# TLE985x register map
Vendor: Infineon Technologies AG; File version: 1.3
CPU: CM0 r0p0, little endian, no MPU, no FPU, 2 interrupt priority bits
Registers are 32-bit, read-write, no defined reset value unless marked. A register's access mark holds for its fields unless they carry their own. Offsets are from the block's base; [hi:lo] are bit positions; {n}, {i} and the like mark numbered series; 'fields as' and 'values as' point back to an identical list.

## BDRV
Base 0x40034000
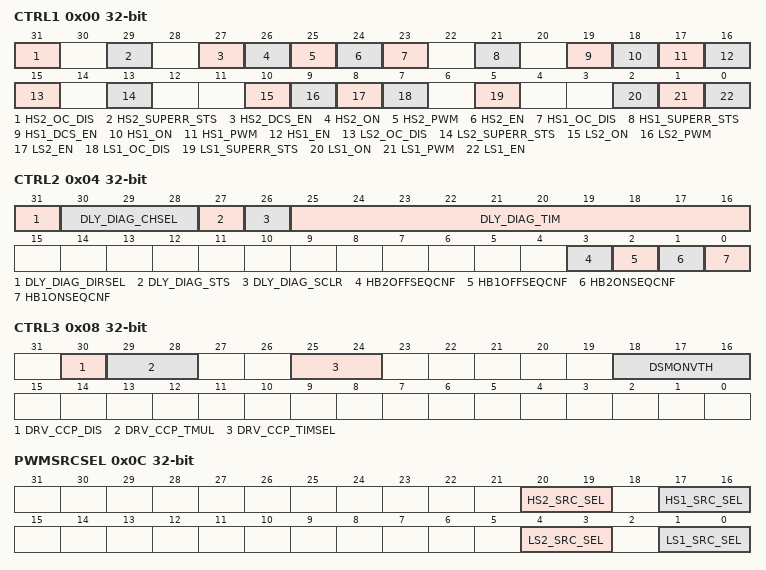
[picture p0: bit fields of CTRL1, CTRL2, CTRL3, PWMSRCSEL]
0x00 CTRL1 access per field — H-Bridge Driver Control 1
  [31] HS2_OC_DIS rw — High Side Driver Overcurrent Shutdown Select
    0=Global_Shutdown (all bridges will be shut down in case of overcurrent); 1=Local_Shutdown (only local driver will be shut down in case of overcurrent)
  [29] HS2_SUPERR_STS ro — High Side Driver 2 Supply Error Status
    0=NORMAL (supply is in required range.); 1=SUPPLY_ERROR (detected; this flag is an OR of the VSD_x_STS and VCP_x_STS flags.)
  [27] HS2_DCS_EN rw — High Side Driver 2 Diagnosis Current Source Enable
    0=DISABLE (disable current source); 1=ENABLE (enable current source; short diagnosis can be performed by evaluating the LSx/HSx_DS_STS Flag)
  [26] HS2_ON rw — High Side Driver 2 On
    0=OFF (Driver off); 1=ON (Driver on)
  [25] HS2_PWM rw — High Side Driver 2 PWM Enable
    0=DISABLE (disables control by PWM input); 1=ENABLE (enables control by PWM input)
  [24] HS2_EN rw — High Side Driver 2 Enable
    0=DISABLE (Driver circuit power off); 1=ENABLE (Driver circuit power on)
  [23] HS1_OC_DIS rw — High Side Driver Overcurrent Shutdown Select
    values as HS2_OC_DIS
  [21] HS1_SUPERR_STS ro — High Side Driver 1 Supply Error Status
    0=NORMAL (supply is in required range.); 1=SUPPLY_ERROR (detected; this flag is an OR of the VDS_x_STS and VCP_x_STS flags.)
  [19] HS1_DCS_EN rw — High Side Driver 1 Diagnosis Current Source Enable
    values as HS2_DCS_EN
  [18] HS1_ON rw — High Side Driver 1 On
    0=OFF (Driver off); 1=ON (Driver on)
  [17] HS1_PWM rw — High Side Driver 1 PWM Enable
    values as HS2_PWM
  [16] HS1_EN rw — High Side Driver 1 Enable
    values as HS2_EN
  [15] LS2_OC_DIS rw — Low Side Driver Overcurrent Shutdown Select
    values as HS2_OC_DIS
  [13] LS2_SUPERR_STS ro — Low Side Driver 2 Supply Error Status
    values as HS1_SUPERR_STS
  [10] LS2_ON rw — Low Side Driver 2 On
    0=OFF (Driver off); 1=ON (Driver on)
  [9] LS2_PWM rw — Low Side Driver 2 PWM Enable
    values as HS2_PWM
  [8] LS2_EN rw — Low Side Driver 2 Enable
    values as HS2_EN
  [7] LS1_OC_DIS rw — Low Side Driver 1 Overcurrent Shutdown Select
    values as HS2_OC_DIS
  [5] LS1_SUPERR_STS ro — Low Side Driver 1 Supply Error Status
    values as HS1_SUPERR_STS
  [2] LS1_ON rw — Low Side Driver 1 On
    0=OFF (Driver off); 1=ON (Driver on)
  [1] LS1_PWM rw — Low Side Driver 1 PWM Enable
    values as HS2_PWM
  [0] LS1_EN rw — Low Side Driver 1 Enable
    values as HS2_EN
0x04 CTRL2 access per field — H-Bridge Driver Control 2
  [31] DLY_DIAG_DIRSEL rw — Ext. power diag timer on / off select
    0=TURN OFF (measure turn off time); 1=TURN ON (measure turn on time)
  [30:28] DLY_DIAG_CHSEL rw — Ext. power diag timer channel select
    0=DISABLE (diag timer deactivated.); 1=HB1 LS select (measure LS1 on/off delay time.); 2=HB2 LS select (measure LS2 on/off delay time.); 5=HB1 HS select (measure HS1 on/off delay time.); 6=HB2 HS select (measure HS2 on/off delay time.)
  [27] DLY_DIAG_STS ro — Ext. power diag timer valid flag
    0=Diag_timer_invalid (diag timer measurement ongoing); 1=Diag_timer_valid (diag timer measurement finished)
  [26] DLY_DIAG_SCLR wo — Ext. power diag timer valid flag clear
    0=Diag timer valid not clear; 1=Diag timer valid clear
  [25:16] DLY_DIAG_TIM ro — Ext. power diag timer result register
  [3] HB2OFFSEQCNF rw — Half Bridge 2 Off Sequencer Configuration
    0=Normal Mode (OFF-Sequencer is disabled and driver operates with constant current.); 1=Sequencer Mode (OFF-Sequencer is enabled.)
  [2] HB1OFFSEQCNF rw — Half Bridge 1 Off Sequencer Configuration
    values as HB2OFFSEQCNF
  [1] HB2ONSEQCNF rw — Half Bridge 2 On Sequencer Configuration
    0=Normal Mode (ON-Sequencer is disabled and driver operates with constant current.); 1=Sequencer Mode (ON-Sequencer is enabled.)
  [0] HB1ONSEQCNF rw — Half Bridge 1 On Sequencer Configuration
    values as HB2ONSEQCNF
0x08 CTRL3 — H-Bridge Driver Control 3
  [30] DRV_CCP_DIS — Dynamic cross conduction protection Disable
    0=CCP Enable (dynamic ccp is active.); 1=CCP Disable (dynamic ccp is disabled, delayed gate clamp remains active.)
  [29:28] DRV_CCP_TMUL — Multiplier bits for cross conduction time settings in register DRV_CCP_TIMSEL
    0=MUL1 (DRV_CCP_TIMSEL value is multiplied by 1); 1=MUL2 (DRV_CCP_TIMSEL value is multiplied by 2); 2=MUL4 (DRV_CCP_TIMSEL value is multiplied by 4); 3=MUL8 (DRV_CCP_TIMSEL value is multiplied by 8)
  [25:24] DRV_CCP_TIMSEL — Minimum cross conduction protection time setting
    0=0.2us (200ns cross conduction protection time); 1=0.4us (400ns cross conduction protection time); 2=0.8us (800ns cross conduction protection time); 3=1.6us cross conduction protection time
  [18:16] DSMONVTH — Voltage Threshold for Drain-Source Monitoring of external FETs
    0=0.125_V (Threshold 0 for VDS at 0.125 V); 1=0.25_V (Threshold 1 for VDS at 0.25 V); 2=0.50_V (Threshold 2 for VDS at 0.50 V); 3=0.75_V (Threshold 3 for VDS at 0.75 V); 4=1.00_V (Threshold 4 for VDS at 1.00 V); 5=1.25_V (Threshold 5 for VDS at 1.25 V); 6=1.50_V (Threshold 6 for VDS at 1.50 V); 7=1.75_V (Threshold 7 for VDS at 1.75 V)
0x0C PWMSRCSEL — PWM Source Selection Register
  [all] fields
    0=CC60 (PWM output of CCU6); 1=CC61 (PWM output of CCU6); 2=COUT60 (PWM output of CCU6); 3=COUT61 (PWM output of CCU6)
  [20:19] HS2_SRC_SEL — HS2 PWM Source Selection
  [17:16] HS1_SRC_SEL — HS1 PWM Source Selection
  [4:3] LS2_SRC_SEL — LS2 PWM Source Selection
  [1:0] LS1_SRC_SEL — LS1 PWM Source Selection
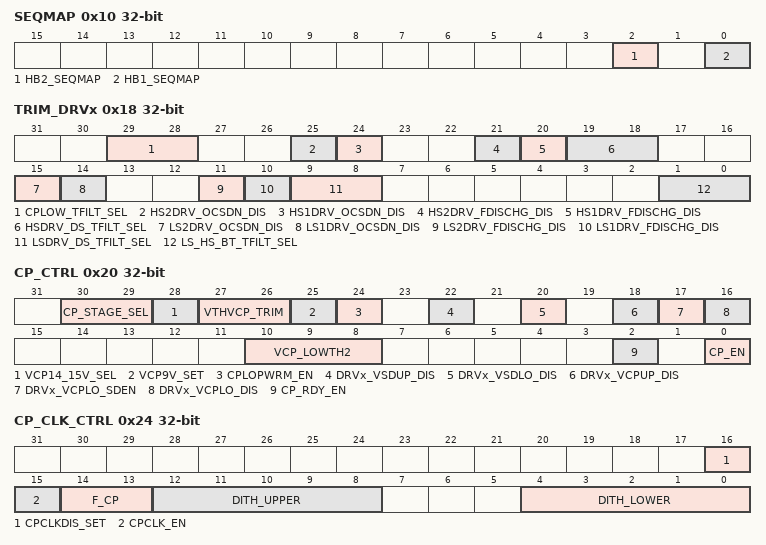
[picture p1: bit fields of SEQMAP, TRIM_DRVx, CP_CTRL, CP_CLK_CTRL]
0x10 SEQMAP — Slewrate Sequencer Mapping Register
  [2] HB2_SEQMAP — Half Bridge 2 Sequencer Mapping
    0=LS2 (slew rate sequencer is mapped to LS2); 1=HS2 (slew rate sequencer is mapped to HS2)
  [0] HB1_SEQMAP — Half Bridge 1 Sequencer Mapping
    0=LS1 (slew rate sequencer is mapped to LS1); 1=HS1 (slew rate sequencer is mapped to HS1)
0x18 TRIM_DRVx — Trimming of Driver
  [29:28] CPLOW_TFILT_SEL — Filter Time for Charge Pump Voltage Low Diagnosis
    0=4 us filter time; 1=8 us filter time; 2=16 us filter time; 3=32 us filter time
  [25] HS2DRV_OCSDN_DIS — High Side 2 Predriver in overcurrent situation disable
    0=Enable (Predriver shutdown in overcurrent situation enable); 1=Disable (Predriver shutdown in overcurrent situation disable)
  [24] HS1DRV_OCSDN_DIS — High Side 1 Predriver in overcurrent situation disable
    values as HS2DRV_OCSDN_DIS
  [21] HS2DRV_FDISCHG_DIS — High Side 2 Predriver fast discharge disable
    0=Enable (Predriver shutdown fast discharge enable); 1=Disable (Predriver shutdown fast discharge disable)
  [20] HS1DRV_FDISCHG_DIS — High Side 1 Predriver fast discharge disable
    values as HS2DRV_FDISCHG_DIS
  [19:18] HSDRV_DS_TFILT_SEL — Filter Time for Drain-Source Monitoring of High Side Drivers
    0=1 us filter time; 1=2 us filter time; 2=4 us filter time; 3=8 us filter time
  [15] LS2DRV_OCSDN_DIS — Low Side 2 Predriver in overcurrent situation disable
    values as HS2DRV_OCSDN_DIS
  [14] LS1DRV_OCSDN_DIS — Low Side 1 Predriver in overcurrent situation disable
    values as HS2DRV_OCSDN_DIS
  [11] LS2DRV_FDISCHG_DIS — Low Side 2 Predriver fast discharge disable
    values as HS2DRV_FDISCHG_DIS
  [10] LS1DRV_FDISCHG_DIS — Low Side 1 Predriver fast discharge disable
    values as HS2DRV_FDISCHG_DIS
  [9:8] LSDRV_DS_TFILT_SEL — Filter Time for Drain-Source Monitoring of Low Side Drivers
    values as HSDRV_DS_TFILT_SEL
  [1:0] LS_HS_BT_TFILT_SEL — Blanking Time for Drain-Source Monitoring of Low / High Side Drivers
    values as HSDRV_DS_TFILT_SEL
0x20 CP_CTRL — Charge Pump Control and Status Register
  [30:29] CP_STAGE_SEL — Charge Pump Output Voltage Trimming
    0=2-stage mode enabled; 1=1-stage1 (single stage mode enable (1st stage)); 2=1-stage2 (single stage mode enable (2nd stage)); 3=automatic switch to single stage mode above 18V VSD (2nd stage) and switching back to 2-stage mode below 17V VSD
  [28] VCP14_15V_SEL — Charge Pump 15V/14V Output Voltage Sel
    0=14V (output voltage set to 14V); 1=15V (output voltage set to 15V)
  [27:26] VTHVCP_TRIM — Charge Pump Output Voltage Trimming
    0=0.0_V (default); 1=0.5_V (plus 0.5V nom at 15V); 2=1.0_V (plus 1.0V nom at 15V); 3=1.5_V (plus 1.5V nom at 15V)
  [25] VCP9V_SET — Charge Pump 9 V Output Voltage Set
    0=15_14V Set (output voltage set according to VCP14_15V_SEL); 1=9V Set (output voltage set to 9V)
  [24] CPLOPWRM_EN — Charge Pump Low Power Mode Enable
    0=Low Power Mode Disable (low power mode inactive); 1=Low Power Mode Enable (low power mode active)
  [22] DRVx_VSDUP_DIS — Driver On VSD Upper Voltage Disable
    0=Driver Enable (DRVx on VSD overvoltage enable.); 1=Driver Disable (DRVx on VSD overvoltage disable.)
  [20] DRVx_VSDLO_DIS — Driver On VSD Lower Voltage Disable
    0=Driver Enable (DRVx on VSD undervoltage enable.); 1=Driver Disable (DRVx on VSD undervoltage disable.)
  [18] DRVx_VCPUP_DIS — Driver On Charge Pump Upper Voltage Disable
    0=Driver Enable (DRVx on Charge Pumpe overvoltage enable.); 1=Driver Disable (DRVx on Charge Pump overvoltage disable.)
  [17] DRVx_VCPLO_SDEN — Driver Charge Pump Low Voltage Shut-Down
    0=Shut-Down Disable (DRVx Shut-Down for Charge Pump undervoltage disable.); 1=Shut-Down Enable (DRVx Shut-Down for Charge Pump undervoltage enable.)
  [16] DRVx_VCPLO_DIS — Driver On Charge Pump Low Voltage Disable
    0=Driver Enable (DRVx on Charge Pump undervoltage enable.); 1=Driver Disable (DRVx on Charge Pump undervoltage disable.)
  [10:8] VCP_LOWTH2 — Charge Pump Output Voltage Lower Threshold Detection Level
    0=7.325_V (Threshold 0); 1=7.654_V (Threshold 1); 2=7.982_V (Threshold 2); 3=8.309_V (Threshold 3); 4=8.638_V (Threshold 4); 5=8.966_V (Threshold 5); 6=9.293_V (Threshold 6); 7=9.620_V (Threshold 7)
  [2] CP_RDY_EN — Bridge Driver on Charge Pump Ready Enable
    0=OFF (Bridge Driver can be immediately enabled); 1=ON (Bridge Driver can only be enabled when Charge Pump is ready)
  [0] CP_EN — Charge Pump Enable
    0=DISABLE (Charge Pump, circuit power off); 1=ENABLE (Charge Pump, circuit power on)
0x24 CP_CLK_CTRL — Charge Pump Clock Control Register
  [16] CPCLKDIS_SET — Charge Pump Clock Set If Disabled
    0=LOW (Charge Pump Clock is 0 if disabled); 1=HIGH (Charge Pump Clock is 1 if disabled)
  [15] CPCLK_EN — Charge Pump Clock Enable
    0=DISABLE (Charge Pump Clock is switched off and has value of according to CPCLKDIS_SET); 1=ENABLE (Charge Pump Clock is running)
  [14:13] F_CP — MSB of CP_CLK divider
  [12:8] DITH_UPPER — CP_CLK upper frequency boundary during dithering
  [4:0] DITH_LOWER — CP_CLK lower frequency boundary during dithering
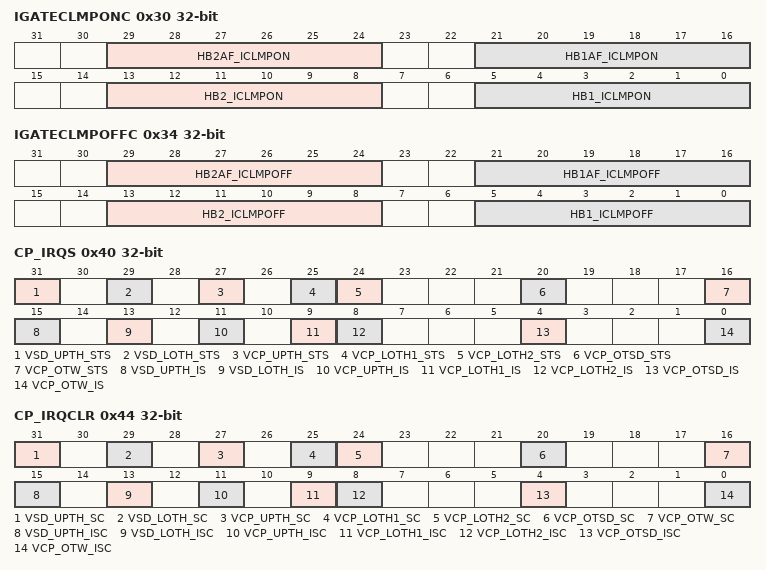
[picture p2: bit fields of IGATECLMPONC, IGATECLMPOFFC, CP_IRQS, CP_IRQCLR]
0x30 IGATECLMPONC — Gate Current Clamping Value in ON State
  [all] fields
    0=min. current (ICHGmin); 63=max. current (ICHGmax)
  [29:24] HB2AF_ICLMPON — Half Bridge 2-active freewheeling-current clamping value for ON state
  [21:16] HB1AF_ICLMPON — Half Bridge 1-active freewheeling-current clamping value for ON state
  [13:8] HB2_ICLMPON — Half Bridge 2-current clamping value for ON state
  [5:0] HB1_ICLMPON — Half Bridge 1-current clamping value for ON state
0x34 IGATECLMPOFFC — Gate Current Clamping Value in OFF State
  [all] fields
    0=min. current (IDISCHGmin); 63=max. current (IDISCHGmax)
  [29:24] HB2AF_ICLMPOFF — Half Bridge 2-active freewheeling-current clamping value for OFF state
  [21:16] HB1AF_ICLMPOFF — Half Bridge 1-active freewheeling-current clamping value for OFF state
  [13:8] HB2_ICLMPOFF — Half Bridge 2-current clamping value for OFF state
  [5:0] HB1_ICLMPOFF — Half Bridge 1-current clamping value for OFF state
0x40 CP_IRQS — Charge Pump Status Register
  [31] VSD_UPTH_STS — Driver Supply MU High Status
    0=ok (Driver Supply Voltage ok, no overvoltage detected); 1=too_high (Driver Supply Voltage too high, overvoltage on VSD Pin detected)
  [29] VSD_LOTH_STS — Driver Supply MU Low Status
    0=ok (Driver Supply Voltage ok, no undervoltage detected.); 1=too_low (Driver Supply Voltage too low, undervoltage on VSD Pin detected.)
  [27] VCP_UPTH_STS — Charge Pump MU High Status
    0=ok (Charge Pump Output Voltage ok, no overvoltage detected); 1=too_high (Charge Pump Output Voltage too high, overvoltage on charge pump output detected)
  [25] VCP_LOTH1_STS — Charge Pump MU Low Status
    0=ok (Charge Pump Output Voltage ok, no undervoltage detected.); 1=too_low (Charge Pump Output Voltage too low, undervoltage on chargepump output detected.)
  [24] VCP_LOTH2_STS — Charge Pump Low Status
    values as VCP_LOTH1_STS
  [20] VCP_OTSD_STS — Charge Pump Overtemperature Shutdown Status
    0=ok (Charge Pump Overtemperature Shutdown Threshold not reached, no charge pump overtemperature shutdown detected.); 1=shutdown (Charge Pump Overtemperature Shutdown, overtemperature shutdown on charge pump occured.)
  [16] VCP_OTW_STS — Charge Pump Overtemperature Warning Status
    0=ok (Charge Pump Temperature ok, no charge pump overtemperature warning detected.); 1=warning (harge Pump Overtemperature Warning, overtemperature threshold on charge pump reached.)
  [15] VSD_UPTH_IS — Driver Supply MU High Interrupt Status
    values as VSD_UPTH_STS
  [13] VSD_LOTH_IS — Driver Supply MU Low Interrupt Status
    values as VSD_LOTH_STS
  [11] VCP_UPTH_IS — Charge Pump MU High Interrupt Status
    values as VCP_UPTH_STS
  [9] VCP_LOTH1_IS — Charge Pump MU Low Interrupt Status
    0=ok (Charge Pump Output Voltage ok, no undervoltage detected.); 1=too_low (Charge Pump Output Voltage too low, undervoltage on charge pump output detected.)
  [8] VCP_LOTH2_IS — Charge Pump Low Interrupt Status
    values as VCP_LOTH1_STS
  [4] VCP_OTSD_IS — Charge Pump Overtemperature Shutdown Interrupt Status
    values as VCP_OTSD_STS
  [0] VCP_OTW_IS — Charge Pump Overtemperature Warning Interrupt Status
    0=ok (Charge Pump Temperature ok, no charge pump overtemperature warning detected.); 1=warning (Charge Pump Overtemperature Warning, overtemperature threshold on charge pump reached.)
0x44 CP_IRQCLR wo — Charge Pump Interrupt Status Clear Register
  [all] fields
    0=no Clear; 1=Clear
  [31] VSD_UPTH_SC — Driver Supply MU High Status Clear
  [29] VSD_LOTH_SC — Driver Supply MU Low Status Clear
  [27] VCP_UPTH_SC — Charge Pump MU High Status Clear
  [25] VCP_LOTH1_SC — Charge Pump MU Low Status Clear
  [24] VCP_LOTH2_SC — Charge Pump Low Status Clear
  [20] VCP_OTSD_SC — Charge Pump Over-temperature Shutdown Status Clear
  [16] VCP_OTW_SC — Charge Pump Over-temperature Warning Status Clear
  [15] VSD_UPTH_ISC — Driver Supply MU High Interrupt Status Clear
  [13] VSD_LOTH_ISC — Driver Supply MU Low Interrupt Status Clear
  [11] VCP_UPTH_ISC — Charge Pump MU High Interrupt Status Clear
  [9] VCP_LOTH1_ISC — Charge Pump MU Low Interrupt Status Clear
  [8] VCP_LOTH2_ISC — Charge Pump Low Interrupt Status Clear
  [4] VCP_OTSD_ISC — Charge Pump Over-temperature Shutdown Interrupt Status Clear
  [0] VCP_OTW_ISC — Charge Pump Over-temperature Warning Interrupt Status Clear
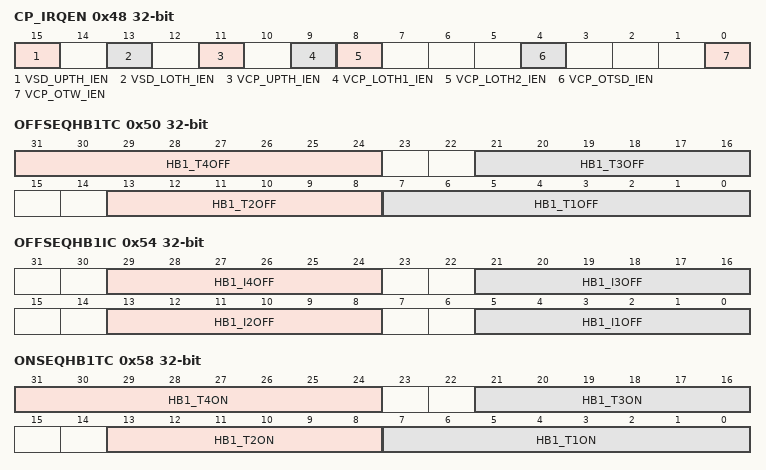
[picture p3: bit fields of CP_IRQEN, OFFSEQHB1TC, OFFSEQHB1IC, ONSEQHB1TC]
0x48 CP_IRQEN — Charge Pump Interrupt Enable Register
  [all] fields
    0=disable; 1=enable
  [15] VSD_UPTH_IEN — Driver Supply MU High Interrupt Enable
  [13] VSD_LOTH_IEN — Driver Supply MU Low Interrupt Enable
  [11] VCP_UPTH_IEN — Charge Pump MU High Interrupt Enable
  [9] VCP_LOTH1_IEN — Charge Pump MU Low Interrupt Enable
  [8] VCP_LOTH2_IEN — Charge Pump Low Interrupt Enable
  [4] VCP_OTSD_IEN — Charge Pump Over-temperature Shutdown Interrupt Enable
  [0] VCP_OTW_IEN — Charge Pump Over-temperature Warning Interrupt Enable
0x50 OFFSEQHB1TC — Turn-off Slewrate Sequencer Half Bridge 1 Time Control
  [31:24] HB1_T4OFF — Half Bridge 1-slew rate sequencer off-phase 4 time setting
    0=50ns phase duration; 255=12.8us phase duration
  [21:16] HB1_T3OFF — Half Bridge 1-slew rate sequencer off-phase 3 time setting
    0=50ns phase duration; 63=3.2us phase duration
  [13:8] HB1_T2OFF — Half Bridge 1-slew rate sequencer off-phase 2 time setting
    0=50ns phase duration; 63=3.2us phase duration
  [7:0] HB1_T1OFF — Half Bridge 1-slew rate sequencer off-phase 1 time setting
    0=50ns phase duration; 255=12.8us phase duration
0x54 OFFSEQHB1IC — Turn-off Slewrate Sequencer Half Bridge 1 Current Control
  [all] fields
    0=min. current (IDISCHGmin); 63=max. current (IDISCHGmax)
  [29:24] HB1_I4OFF — Half Bridge 1-slew rate sequencer off-phase 4 current setting
  [21:16] HB1_I3OFF — Half Bridge 1-slew rate sequencer off-phase 3 current setting
  [13:8] HB1_I2OFF — Half Bridge 1-slew rate sequencer-off phase 2 current setting
  [5:0] HB1_I1OFF — Half Bridge 1-slew rate sequencer off-phase 1 current setting
0x58 ONSEQHB1TC — Turn-on Slewrate Sequencer Half Bridge 1 Time Control
  [31:24] HB1_T4ON — Half Bridge 1-slew rate sequencer on-phase 4 time setting
    0=50ns phase duration; 255=12.8us phase duration
  [21:16] HB1_T3ON — Half Bridge 1-slew rate sequencer on-phase 3 time setting
    0=50ns phase duration; 63=3.2us phase duration
  [13:8] HB1_T2ON — Half Bridge 1-slew rate sequencer on-phase 2 time setting
    0=50ns phase duration; 63=3.2us phase duration
  [7:0] HB1_T1ON — Half Bridge 1-slew rate sequencer on-phase 1 time setting
    0=50ns phase duration; 255=12.8us phase duration
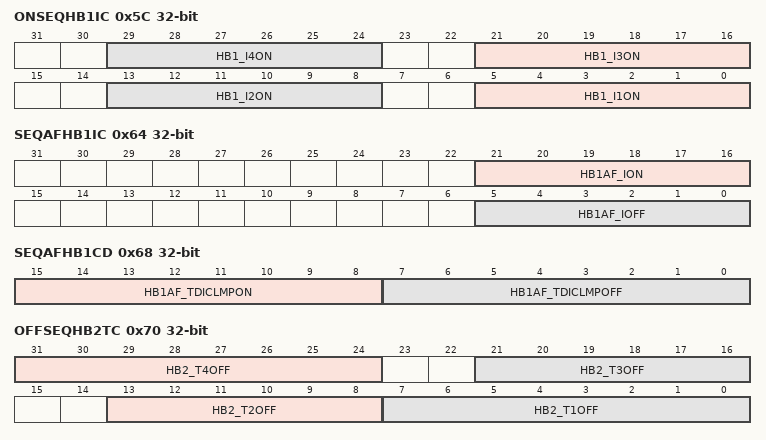
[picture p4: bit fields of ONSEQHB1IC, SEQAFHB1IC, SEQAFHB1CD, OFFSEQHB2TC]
0x5C ONSEQHB1IC — Turn-on Slewrate Sequencer Half Bridge 1 Current Control
  [all] fields
    0=min. current (ICHGmin); 63=max. current (ICHGmax)
  [8n-3:8n-8] HB1_I{n}ON (n=1..4) — Half Bridge 1-slew rate sequencer on-phase {n} current setting
0x64 SEQAFHB1IC — Slewrate Sequencer-Active Freewheeling-Half Bridge 1 Current Control
  [21:16] HB1AF_ION — Half Bridge 1-active freewheeling-slew rate sequencer on-phase current setting
    0=min. current (IDISCHGmin); 63=max. current (IDISCHGmax)
  [5:0] HB1AF_IOFF — Half Bridge 1-active freewheeling-slew rate sequencer off-phase current setting
    0=min. current (IDISCHGmin); 63=max. current (IDISCHGmax)
0x68 SEQAFHB1CD — Slewrate Sequencer-Active Freewheeling- Half Bridge 1 Clamping Current Delay
  [15:8] HB1AF_TDICLMPON — Clamping current delay during active freewheeling for switch on
    0=50ns phase duration; 255=12.8us phase duration
  [7:0] HB1AF_TDICLMPOFF — Clamping current delay during active freewheeling for switch off
    0=50ns phase duration; 255=12.8us phase duration
0x70 OFFSEQHB2TC — Turn-off Slewrate Sequencer Half Bridge 2 Time Control
  [31:24] HB2_T4OFF — Half Bridge 2-slew rate sequencer off-phase 4 time setting
    0=50ns phase duration; 255=12.8us phase duration
  [21:16] HB2_T3OFF — Half Bridge 2-slew rate sequencer off-phase 3 time setting
    0=50ns phase duration; 63=3.2us phase duration
  [13:8] HB2_T2OFF — Half Bridge 2-slew rate sequencer off-phase 2 time setting
    0=50ns phase duration; 63=3.2us phase duration
  [7:0] HB2_T1OFF — Half Bridge 2-slew rate sequencer off-phase 1 time setting
    0=50ns phase duration; 255=12.8us phase duration
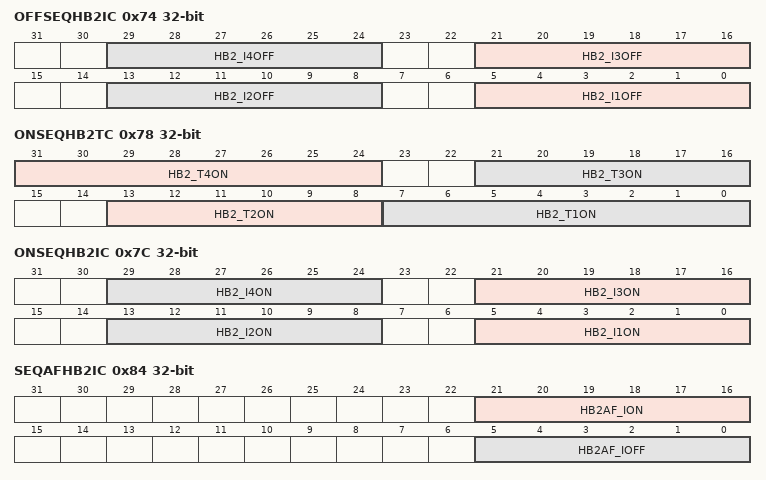
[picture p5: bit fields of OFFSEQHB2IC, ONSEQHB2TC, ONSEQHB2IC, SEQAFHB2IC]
0x74 OFFSEQHB2IC — Turn-off Slewrate Sequencer Half Bridge 2 Current Control
  [all] fields
    0=min. current (IDISCHGmin); 63=max. current (IDISCHGmax)
  [8n-3:8n-8] HB2_I{n}OFF (n=1..4) — Half Bridge 2-slew rate sequencer off-phase {n} current setting
0x78 ONSEQHB2TC — Turn-on Slewrate Sequencer Half Bridge 2 Time Control
  [31:24] HB2_T4ON — Half Bridge 2-slew rate sequencer on-phase 4 time setting
    0=50ns phase duration; 255=12.8us phase duration
  [21:16] HB2_T3ON — Half Bridge 2-slew rate sequencer on-phase 3 time setting
    0=50ns phase duration; 63=3.2us phase duration
  [13:8] HB2_T2ON — Half Bridge 2-slew rate sequencer on-phase 2 time setting
    0=50ns phase duration; 63=3.2us phase duration
  [7:0] HB2_T1ON — Half Bridge 2-slew rate sequencer on-phase 1 time setting
    0=50ns phase duration; 255=12.8us phase duration
0x7C ONSEQHB2IC — Turn-on Slewrate Sequencer Half Bridge 2 Current Control
  [all] fields
    0=min. current (ICHGmin); 63=max. current (ICHGmax)
  [8n-3:8n-8] HB2_I{n}ON (n=1..4) — Half Bridge 2-slew rate sequencer on-phase {n} current setting
0x84 SEQAFHB2IC — Slewrate Sequencer-Active Freewheeling- Half Bridge 2 Current Control
  [21:16] HB2AF_ION — Half Bridge 2-active freewheeling-slew rate sequencer on-phase current setting
    0=min. current (IDISCHGmin); 63=max. current (IDISCHGmax)
  [5:0] HB2AF_IOFF — Half Bridge 2-active freewheeling-slew rate sequencer off-phase current setting
    0=min. current (IDISCHGmin); 63=max. current (IDISCHGmax)
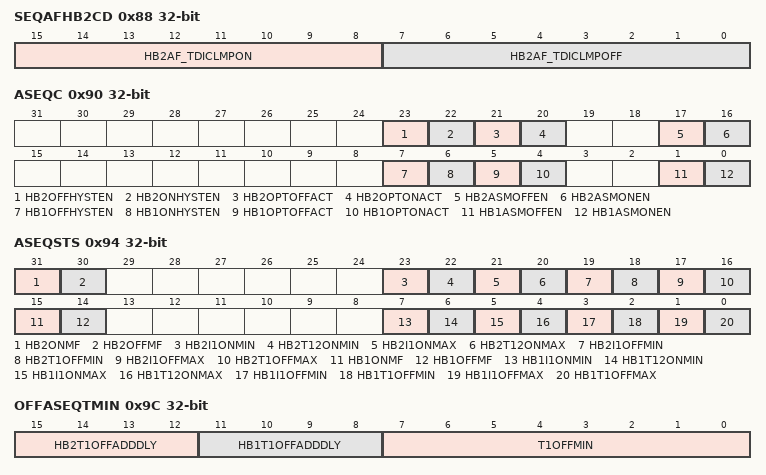
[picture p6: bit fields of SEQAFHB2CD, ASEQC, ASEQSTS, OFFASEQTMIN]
0x88 SEQAFHB2CD — Slewrate Sequencer-Active Freewheeling- Half Bridge 2 Clamping Current Delay
  [15:8] HB2AF_TDICLMPON — Clamping current delay during active freewheeling for switch on
    0=50ns phase duration; 255=12.8us phase duration
  [7:0] HB2AF_TDICLMPOFF — Clamping current delay during active freewheeling for switch off
    0=50ns phase duration; 255=12.8us phase duration
0x90 ASEQC — Adaptive Slewrate Sequencer Control Register
  [23] HB2OFFHYSTEN — Half Bridge 2 Optimizer Hysteresis for Switch Off Enable Bit
    0=OFF (current optimizer hysteresis is not enabled); 1=ON (current optimizer hysteresis is enabled)
  [22] HB2ONHYSTEN — Half Bridge 2 Optimizer Hysteresis for Switch On Enable Bit
    values as HB2OFFHYSTEN
  [21] HB2OPTOFFACT — Half Bridge 2 Optimizer for Switch Off Active Bit
    0=OFF (current optimizer is not active); 1=ON (current optimizer is active)
  [20] HB2OPTONACT — Half Bridge 2 Optimizer for Switch On Active Bit
    values as HB2OPTOFFACT
  [17] HB2ASMOFFEN — Half Bridge 2 Adaptive Sequencer Mode for Switch Off Enable
    0=Disable (adaptive slew rate sequencer is disabled); 1=Enable (adaptive slew rate sequencer is enabled)
  [16] HB2ASMONEN — Half Bridge 2 Adaptive Sequencer Mode for Switch On Enable
    values as HB2ASMOFFEN
  [7] HB1OFFHYSTEN — Half Bridge 1 Optimizer Hysteresis for Switch Off Enable Bit
    values as HB2OFFHYSTEN
  [6] HB1ONHYSTEN — Half Bridge 1 Optimizer Hysteresis for Switch On Enable Bit
    values as HB2OFFHYSTEN
  [5] HB1OPTOFFACT — Half Bridge 1 Optimizer for Switch Off Active Bit
    values as HB2OPTOFFACT
  [4] HB1OPTONACT — Half Bridge 1 Optimizer for Switch On Active Bit
    values as HB2OPTOFFACT
  [1] HB1ASMOFFEN — Half Bridge 1 Adaptive Sequencer Mode for Switch Off Enable
    values as HB2ASMOFFEN
  [0] HB1ASMONEN — Half Bridge 1 Adaptive Sequencer Mode for Switch On Enable
    values as HB2ASMOFFEN
0x94 ASEQSTS ro — Adaptive Slewrate Sequencer Status Register
  [31] HB2ONMF — Half Bridge 2- On Adaptive Mode Measurement Failure
    0=no Error (No Measurement Failure); 1=Error (Measurement Failure)
  [30] HB2OFFMF — Half Bridge 2- Off Adaptive Mode Measurement Failure
    values as HB2ONMF
  [23] HB2I1ONMIN — Half Bridge 2-I1 On Min Value reached
    0=no Error (Min Value not reached); 1=Error (Min Value reached)
  [22] HB2T12ONMIN — Half Bridge 2-T12 On Min Value reached
    values as HB2I1ONMIN
  [21] HB2I1ONMAX — Half Bridge 2-I1 On Max Value reached
    0=no Error (Max Value not reached); 1=Error (Max Value reached)
  [20] HB2T12ONMAX — Half Bridge 2-T12 On Max Value reached
    values as HB2I1ONMAX
  [19] HB2I1OFFMIN — Half Bridge 2-I1 Off Min Value reached
    values as HB2I1ONMIN
  [18] HB2T1OFFMIN — Half Bridge 2-T1 Off Min Value reached
    values as HB2I1ONMIN
  [17] HB2I1OFFMAX — Half Bridge 2-I1 Off Max Value reached
    values as HB2I1ONMAX
  [16] HB2T1OFFMAX — Half Bridge 2-T1 Off Max Value reached
    values as HB2I1ONMAX
  [15] HB1ONMF — Half Bridge 1-On Adaptive Mode Measurement Failure
    values as HB2ONMF
  [14] HB1OFFMF — Half Bridge 1-Off Adaptive Mode Measurement Failure
    values as HB2ONMF
  [7] HB1I1ONMIN — Half Bridge 1-I1 On Min Value reached
    values as HB2I1ONMIN
  [6] HB1T12ONMIN — Half Bridge 1-T12 On Min Value reached
    values as HB2I1ONMIN
  [5] HB1I1ONMAX — Half Bridge 1-I1 On Max Value reached
    values as HB2I1ONMAX
  [4] HB1T12ONMAX — Half Bridge 1-T12 On Max Value reached
    values as HB2I1ONMAX
  [3] HB1I1OFFMIN — Half Bridge 1-I1 Off Min Value reached
    values as HB2I1ONMIN
  [2] HB1T1OFFMIN — Half Bridge 1-T1 Off Min Value reached
    values as HB2I1ONMIN
  [1] HB1I1OFFMAX — Half Bridge 1-I1 Off Max Value reached
    values as HB2I1ONMAX
  [0] HB1T1OFFMAX — Half Bridge 1-T1 Off Max Value reached
    values as HB2I1ONMAX
0x98 ONASEQTMIN — Turn ON Adaptive Slewrate Sequencer Minimum Time Setting
  [7:0] T12ONMIN — Slew rate sequencer on-phase 12 min. time setting
    0=50ns phase duration; 255=12.8us phase duration
0x9C OFFASEQTMIN — Turn OFF Adaptive Slewrate Sequencer Minimum Time Setting
  [15:12] HB2T1OFFADDDLY — HB2 adaptive sequencer T1OFF additional delay setting.
    0=0ns (0ns added to HB2T1OFF); 15=750ns added to HB2T1OFF
  [11:8] HB1T1OFFADDDLY — HB1 adaptive sequencer T1OFF additional delay setting.
    0=0ns (0ns added to HB1T1OFF); 15=750ns added to HB1T1OFF
  [7:0] T1OFFMIN — Slew rate sequencer off-phase 1 min. time setting
    0=50ns phase duration; 255=12.8us phase duration
0xA0 ASEQIONMIN — Adaptive Slewrate Sequencer On Phase Minimum Current Setting
  [5:0] I1ONMIN — Slew rate sequencer on-phase 1 min. current setting
    0=min. current (ICHGmin); 63=max. current (ICHGmax)
0xA4 ASEQIOFFMIN — Adaptive Slewrate Sequencer Off Phase Minimum Current Setting
  [5:0] I1OFFMIN — Slew rate sequencer off-phase 1 min. current setting
    0=min. current (IDISCHGmin); 63=max. current (IDISCHGmax)
0xA8 ONASEQTMAX — Adaptive Slewrate On Sequencer Maximum Time Setting
  [7:0] T12ONMAX — Slew rate sequencer on-phase 12 max. time setting
    0=50ns phase duration; 255=12.8us phase duration
0xAC OFFASEQTMAX — Adaptive Slewrate Off Sequencer Maximum Time Setting
  [7:0] T1OFFMAX — Slew rate sequencer off-phase 1 max. time setting
    0=50ns phase duration; 255=12.8us phase duration
0xB0 ASEQIONMAX — Adaptive Slewrate Sequencer On Phase Maximum Current Setting
  [5:0] I1ONMAX — Slew rate sequencer on-phase 1 max. current setting
    0=min. current (ICHGmin); 63=max. current (ICHGmax)
0xB4 ASEQIOFFMAX — Adaptive Slewrate Sequencer Off Phase Maximum Current Setting
  [5:0] I1OFFMAX — Slew rate sequencer off-phase 1 max. current setting
    0=min. current (IDISCHGmin); 63=max. current (IDISCHGmax)
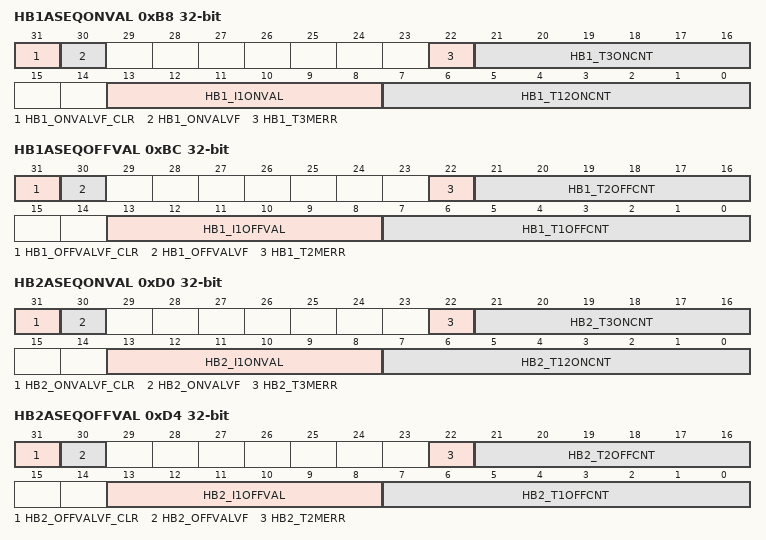
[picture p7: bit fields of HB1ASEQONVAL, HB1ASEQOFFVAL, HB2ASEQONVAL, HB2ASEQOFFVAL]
0xB8 HB1ASEQONVAL access per field — Half Bridge 1 Adaptive Sequencer On Values
  [31] HB1_ONVALVF_CLR wo — Half Bridge 1-Turn on slew rate values Valid Flag - Clear.
    0=NOT CLEAR (no clear of HB1_ONVALVF flag); 1=CLEAR (clear of HB1_ONVALVF flag)
  [30] HB1_ONVALVF rw — Half Bridge 1-Turn on slew rate values - Valid Flag.
    0=NOT VALID (no new valid LS1/HS1_ON values available); 1=VALID (LS1/HS1_ON fields contain valid data and have not been read)
  [22] HB1_T3MERR ro — Half Bridge 1-T3 Measurement Error.
    0=VALID (T3 value valid); 1=ERROR (T3 value not valid - Measurement Error)
  [21:16] HB1_T3ONCNT ro — Half Bridge 1-Turn on slew rate-time value measured from beginning of phase 3 to end of phase 3.
    0=50ns phase duration; 63=3.2us phase duration
  [13:8] HB1_I1ONVAL ro — Half Bridge 1-slew rate sequencer on-phase 1 current setting
    0=min. current (ICHGmin); 63=max. current (ICHGmax)
  [7:0] HB1_T12ONCNT ro — Half Bridge 1-Turn on slew rate-time value measured from beginning of phase 1 to end of phase 2.
    0=50ns phase duration; 255=12.8us phase duration
0xBC HB1ASEQOFFVAL access per field — Half Bridge 1 Adaptive Sequencer Off Values
  [31] HB1_OFFVALVF_CLR wo — Half Bridge 1-Turn off slew rate values Valid Flag - Clear.
    0=NOT CLEAR (no clear of HB1_OFFVALVF flag); 1=CLEAR (clear of HB1_OFFVALVF flag)
  [30] HB1_OFFVALVF rw — Half Bridge 1-Turn off slew rate values - Valid Flag.
    0=NOT VALID (no new valid LS1/HS1_OFF values available); 1=VALID (LS1/HS1_OFF fields contain valid data and have not been read)
  [22] HB1_T2MERR ro — Half Bridge 1-T2 Measurement Error.
    0=VALID (T2 value valid); 1=ERROR (T2 value not valid - Measurement Error)
  [21:16] HB1_T2OFFCNT ro — Half Bridge 1-Turn off slew rate-time value measured from beginning of phase 2 to end of phase 2.
    0=50ns phase duration; 63=3.2us phase duration
  [13:8] HB1_I1OFFVAL ro — Half Bridge 1-slew rate sequencer off-phase 1 current setting
    0=min. current (ICHGmin); 63=max. current (ICHGmax)
  [7:0] HB1_T1OFFCNT ro — Half Bridge 1-Turn off slew rate-time value measured from beginning of phase 1 to end of phase 1.
    0=50ns phase duration; 255=12.8us phase duration
0xD0 HB2ASEQONVAL access per field — Half Bridge 2 Adaptive Sequencer On Values
  [31] HB2_ONVALVF_CLR wo — Half Bridge 2-Turn on slew rate values Valid Flag - Clear.
    0=NOT CLEAR (no clear of HB2_ONVALVF flag); 1=CLEAR (clear of HB2_ONVALVF flag)
  [30] HB2_ONVALVF rw — Half Bridge 2-Turn on slew rate values - Valid Flag.
    0=NOT VALID (no new valid LS2/HS2_ON values available); 1=VALID (LS2/HS2_ON fields contain valid data and have not been read)
  [22] HB2_T3MERR ro — Half Bridge 2-T3 Measurement Error.
    values as HB1ASEQONVAL.HB1_T3MERR
  [21:16] HB2_T3ONCNT ro — Half Bridge 2-Turn on slew rate-time value measured from beginning of phase 3 to end of phase 3.
    0=50ns phase duration; 63=3.2us phase duration
  [13:8] HB2_I1ONVAL ro — Half Bridge 2-slew rate sequencer on-phase 1 current setting
    0=min. current (ICHGmin); 63=max. current (ICHGmax)
  [7:0] HB2_T12ONCNT ro — Half Bridge 2-Turn on slew rate-time value measured from beginning of phase 1 to end of phase 2.
    0=50ns phase duration; 255=12.8us phase duration
0xD4 HB2ASEQOFFVAL access per field — Half Bridge 2 Adaptive Sequencer Off Values
  [31] HB2_OFFVALVF_CLR wo — Half Bridge 2-Turn off slew rate values Valid Flag - Clear.
    0=NOT CLEAR (no clear of HB2_OFFVALVF flag); 1=CLEAR (clear of HB2_OFFVALVF flag)
  [30] HB2_OFFVALVF rw — Half Bridge 2-Turn off slew rate values - Valid Flag.
    0=NOT VALID (no new valid LS2/HS2_OFF values available); 1=VALID (LS2/HS2_OFF fields contain valid data and have not been read)
  [22] HB2_T2MERR ro — Half Bridge 2-T2 Measurement Error.
    values as HB1ASEQOFFVAL.HB1_T2MERR
  [21:16] HB2_T2OFFCNT ro — Half Bridge 2-Turn off slew rate-time value measured from beginning of phase 2 to end of phase 2.
    0=50ns phase duration; 63=3.2us phase duration
  [13:8] HB2_I1OFFVAL ro — Half Bridge 2-slew rate sequencer off-phase 1 current setting
    0=min. current (ICHGmin); 63=max. current (ICHGmax)
  [7:0] HB2_T1OFFCNT ro — Half Bridge 2-Turn off slew rate-time value measured from beginning of phase 1 to end of phase 1.
    0=50ns phase duration; 255=12.8us phase duration
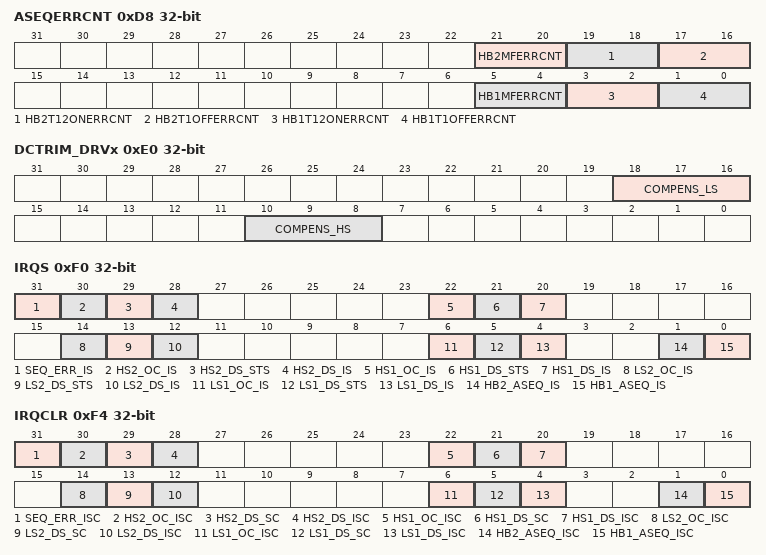
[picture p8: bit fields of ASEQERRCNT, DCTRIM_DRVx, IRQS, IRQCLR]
0xD8 ASEQERRCNT — Adaptive Slewrate Sequencer Error Counter Control Register
  [all] fields
    0=2 Events (Error Flag is set after 2 Events); 1=4 Events (Error Flag is set after 4 Events); 2=8 Events (Error Flag is set after 8 Events); 3=15 Events (Error Flag is set after 15 Events)
  [21:20] HB2MFERRCNT — Half Bridge 2-Measurement Failure Error Counter Setting
  [19:18] HB2T12ONERRCNT — Half Bridge 2-T12 On Error Counter Setting
  [17:16] HB2T1OFFERRCNT — Half Bridge 2-T1 Off Error Counter Setting
  [5:4] HB1MFERRCNT — Half Bridge 1-Measurement Failure Error Counter Setting
  [3:2] HB1T12ONERRCNT — Half Bridge 1-T12 On Error Counter Setting
  [1:0] HB1T1OFFERRCNT — Half Bridge 1-T1 Off Error Counter Setting
0xE0 DCTRIM_DRVx — Current Trimming of Driver
  [18:16] COMPENS_LS — Gain Settings for Low Side Charge Current Compensation
    0=DISABLE (Dynamic Compensation is disabled.); 1=gain_1 (gain setting 1 (min)); 2=gain_2 (gain setting 2); 3=gain_3 (gain setting 3); 4=gain_4 (gain setting 4 (max))
  [10:8] COMPENS_HS — Current Settings for High Side Charge Current Compensation
    values as COMPENS_LS
0xF0 IRQS — H-Bridge Driver Interrupt Status
  [31] SEQ_ERR_IS — Driver Sequence Error Interrupt Status
    0=Driver Sequence ok (no cross current); 1=Driver Sequence fail (HS and LS of same bridge concurrently activated, output protection activated)
  [30] HS2_OC_IS — External High Side 2 FET Over-current Interrupt Status
    0=no over-current Condition occurred; 1=over-current occurred; switch is automatically shut down
  [29] HS2_DS_STS — High Side Driver 2 Drain Source Monitoring Status in OFF-State
    0=no short on external FET (no short detected.); 1=short on external FET detected (short detected.)
  [28] HS2_DS_IS — High Side Driver 2 Drain Source Monitoring Interrupt Status in OFF-State
    values as HS2_DS_STS
  [22] HS1_OC_IS — External High Side 1 FET Over-current Interrupt Status
    0=no over-current Condition occurred; 1=over-current occurred; switch is automatically shutdown
  [21] HS1_DS_STS — High Side Driver 1 Drain Source Monitoring Status in OFF-State
    values as HS2_DS_STS
  [20] HS1_DS_IS — High Side Driver 1 Drain Source Monitoring Interrupt Status in OFF-State
    values as HS2_DS_STS
  [14] LS2_OC_IS — External Low Side 2 FET Over-current Interrupt Status
    values as HS1_OC_IS
  [13] LS2_DS_STS — Low Side Driver 2 Drain Source Monitoring Status in OFF-State
    values as HS2_DS_STS
  [12] LS2_DS_IS — Low Side Driver 2 Drain Source Monitoring Interrupt Status in OFF-State
    values as HS2_DS_STS
  [6] LS1_OC_IS — External Low Side 1 FET Over-current Interrupt Status
    values as HS1_OC_IS
  [5] LS1_DS_STS — Low Side Driver 1 Drain Source Monitoring Status in OFF-State
    values as HS2_DS_STS
  [4] LS1_DS_IS — Low Side Driver 1 Drain Source Monitoring Interrupt Status in OFF-State
    values as HS2_DS_STS
  [1] HB2_ASEQ_IS — Half Bridge 2 Adaptive Sequencer Interrupt Status
    0=no error in SEQ (no sequencer Error detected.); 1=error in SEQ (sequencer Error detected.)
  [0] HB1_ASEQ_IS — Half Bridge 1 Adaptive Sequencer Interrupt Status
    values as HB2_ASEQ_IS
0xF4 IRQCLR wo — H-Bridge Driver Interrupt Status Clear Register
  [all] fields
    0=no Clear; 1=Clear
  [31] SEQ_ERR_ISC — Driver Sequence Error Status Clear
  [30] HS2_OC_ISC — External High Side 2 FET Over-current Status Clear
  [29] HS2_DS_SC — High Side Driver 2 Drain Source Monitoring Status Clear in OFF-State
  [28] HS2_DS_ISC — High Side Driver 2 Drain Source Monitoring Interrupt Status Clear in OFF-State
  [22] HS1_OC_ISC — External High Side 1 FET Over-current Status Clear
  [21] HS1_DS_SC — High Side Driver 1 Drain Source Monitoring Status Clear in OFF-State
  [20] HS1_DS_ISC — High Side Driver 1 Drain Source Monitoring Interrupt Status Clear in OFF-State
  [14] LS2_OC_ISC — External Low Side 2 FET Over-current Status Clear
  [13] LS2_DS_SC — Low Side Driver 2 Drain Source Monitoring Status Clear in OFF-State
  [12] LS2_DS_ISC — Low Side Driver 2 Drain Source Monitoring Interrupt Status Clear in OFF-State
  [6] LS1_OC_ISC — External Low Side 1 FET Over-current Status Clear
  [5] LS1_DS_SC — Low Side Driver 1 Drain Source Monitoring Status Clear in OFF-State
  [4] LS1_DS_ISC — Low Side Driver 1 Drain Source Monitoring Interrupt Status Clear in OFF-State
  [1] HB2_ASEQ_ISC — Half Bridge 2 Adaptive Sequencer Interrupt Status Clear
  [0] HB1_ASEQ_ISC — Half Bridge 1 Adaptive Sequencer Interrupt Status Clear
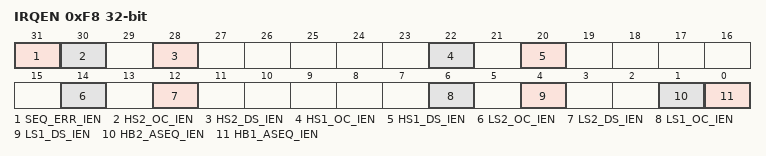
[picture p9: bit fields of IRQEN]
0xF8 IRQEN — H-Bridge Driver Control
  [all] fields
    0=disable; 1=enable
  [31] SEQ_ERR_IEN — Driver Sequence Error Interrupt Enable
  [30] HS2_OC_IEN — External High Side 2 FET Over-current Interrupt Enable
  [28] HS2_DS_IEN — High Side Driver 2 Drain Source Monitoring Interrupt Enable in OFF-State
  [22] HS1_OC_IEN — External High Side 1 FET Over-current Interrupt Enable
  [20] HS1_DS_IEN — High Side Driver 1 Drain Source Monitoring Interrupt Enable in OFF-State
  [14] LS2_OC_IEN — External Low Side 2 FET Over-current Interrupt Enable
  [12] LS2_DS_IEN — Low Side Driver 2 Drain Source Monitoring Interrupt Enable in OFF-State
  [6] LS1_OC_IEN — External Low Side 1 FET Over-current Interrupt Enable
  [4] LS1_DS_IEN — Low Side Driver 1 Drain Source Monitoring Interrupt Enable in OFF-State
  [1] HB2_ASEQ_IEN — Half Bridge 2 Adaptive Sequencer Interrupt Enable
  [0] HB1_ASEQ_IEN — Half Bridge 1 Adaptive Sequencer Interrupt Enable
